# TC37X register map
File version: 1.0.0
CPU: CM4 r0p1, little endian, MPU, FPU, VTOR, 3 interrupt priority bits
Registers are 16-bit, read-write, reset 0x0 unless marked. A register's access mark holds for its fields unless they carry their own. Offsets are from the block's base; [hi:lo] are bit positions; {n}, {i} and the like mark numbered series; 'fields as' and 'values as' point back to an identical list.

## CCU60 — ce_ccusix
Base 0xF0002A00
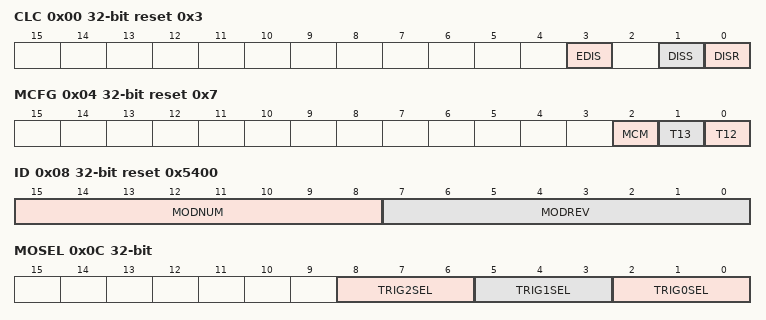
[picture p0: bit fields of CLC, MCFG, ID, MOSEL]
0x00 CLC 32-bit reset 0x3 — Clock Control Register
  [3] EDIS — Sleep Mode Enable Control - EDIS
  [1] DISS ro — Module Disable Status Bit - DISS
  [0] DISR — Module Disable Request Bit - DISR
0x04 MCFG 32-bit ro reset 0x7 — Module Configuration Register
  [2] MCM — Multi-Channel Mode Available - MCM
  [1] T13 — T13 Available - T13
  [0] T12 — T12 Available - T12
0x08 ID 32-bit ro reset 0x5400 (reset mask 0xFFFFFF00) — Module Identification Register
  [15:8] MODNUM — Module Number Value - MODNUM
  [7:0] MODREV — Module Revision Number - MODREV
0x0C MOSEL 32-bit — CCU60 Module Output Select Register
  [8:6] TRIG2SEL — Output Trigger Select for CCU6061 TRIG2
  [5:3] TRIG1SEL — Output Trigger Select for CCU6061 TRIG1
  [2:0] TRIG0SEL — Output Trigger Select for CCU6061 TRIG0
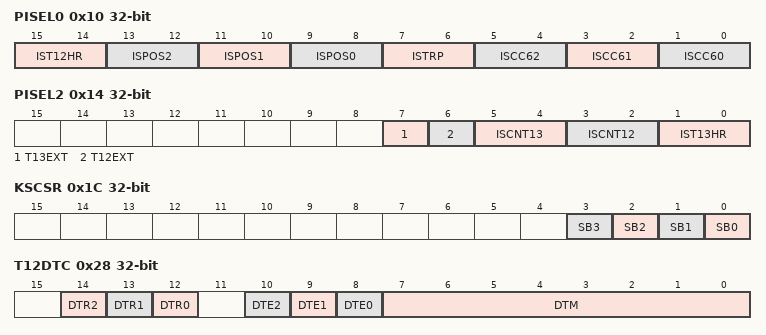
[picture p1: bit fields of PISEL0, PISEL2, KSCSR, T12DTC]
0x10 PISEL0 32-bit — Port Input Select Register 0
  [15:14] IST12HR — Input Select for T12HR - IST12HR
  [13:12] ISPOS2 — Input Select for CCPOS0 ISPOSx (x=0,1,2)
  [11:10] ISPOS1 — Input Select for CCPOS0 ISPOSx (x=0,1,2)
  [9:8] ISPOS0 — Input Select for CCPOS0 ISPOSx (x=0,1,2)
  [7:6] ISTRP — Input Select for CTRAP - ISTRP
  [5:4] ISCC62 — Input Select for CC60 ISCC6x (x=0,1,2)
  [3:2] ISCC61 — Input Select for CC60 ISCC6x (x=0,1,2)
  [1:0] ISCC60 — Input Select for CC60 ISCC6x (x=0,1,2)
0x14 PISEL2 32-bit — Port Input Select Register 2
  [7] T13EXT — Extension for T13HR Inputs - T13EXT
  [6] T12EXT — Extension for T12HR Inputs - T12EXT
  [5:4] ISCNT13 — Input Select for T13 Counting Input - ISCNT13
  [3:2] ISCNT12 — Input Select for T12 Counting Input - ISCNT12
  [1:0] IST13HR — Input Select for T13HR - IST13HR
0x1C KSCSR 32-bit — Kernel State Control Sensitivity Register
  [n] SB{n} (n=0..3) — Sensitivity Block x SBx (x=0,1,2,3)
0x20 T12 32-bit — Timer T12 Counter Register
  [15:0] T12CV — Timer 12 Counter Value - T12CV
0x24 T12PR 32-bit — Timer 12 Period Register
  [15:0] T12PV — T12 Period Value - T12PV
0x28 T12DTC 32-bit — Dead-Time Control Register for Timer12
  [14] DTR2 ro — Dead Time Run Indication Bits DTRx (x=1,2,3)
  [13] DTR1 ro — Dead Time Run Indication Bits DTRx (x=1,2,3)
  [12] DTR0 ro — Dead Time Run Indication Bits DTRx (x=1,2,3)
  [10] DTE2 — Dead Time Enable Bits DTEx (x=0,1,2)
  [9] DTE1 — Dead Time Enable Bits DTEx (x=0,1,2)
  [8] DTE0 — Dead Time Enable Bits DTEx (x=0,1,2)
  [7:0] DTM — Dead-Time - DTM
0x30 CC60R 32-bit ro — Capture/Compare Register for Channel CC60
  [15:0] CCV — Capture/Compare Value - CCV
0x34 CC61R 32-bit ro — Capture/Compare Register for Channel CC61
  [15:0] CCV — Capture/Compare Value - CCV
0x38 CC62R 32-bit ro — Capture/Compare Register for Channel CC62
  [15:0] CCV — Capture/Compare Value - CCV
0x40 CC60SR 32-bit — Capture/Compare Shadow Reg. for Channel CC60
  [15:0] CCS — Shadow Register for Channel x Capture/Compare Value - CCS
0x44 CC61SR 32-bit — Capture/Compare Shadow Reg. for Channel CC61
  fields as CC60SR
0x48 CC62SR 32-bit — Capture/Compare Shadow Reg. for Channel CC62
  fields as CC60SR
0x50 T13 32-bit — Timer T13 Counter Register
  [15:0] T13CV — Timer 13 Counter Value - T13CV
0x54 T13PR 32-bit — Timer 13 Period Register
  [15:0] T13PV — T13 Period Value - T13PV
0x58 CC63R 32-bit ro — Compare Register for T13
  [15:0] CCV — Channel CC63 Compare Value - CCV
0x5C CC63SR 32-bit — Compare Shadow Register for T13
  [15:0] CCS — Shadow Register for Channel CC63 Compare Value - CCS
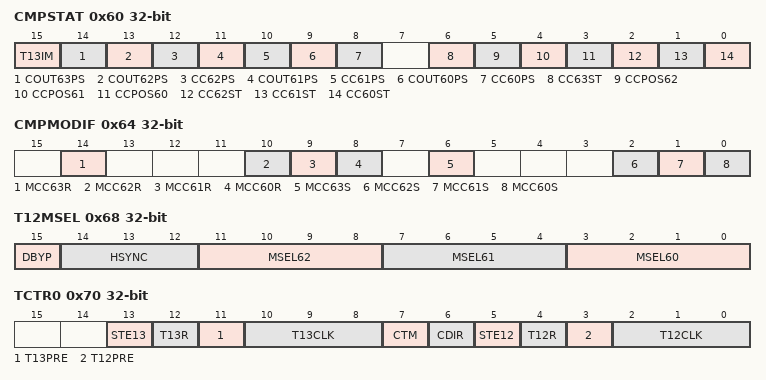
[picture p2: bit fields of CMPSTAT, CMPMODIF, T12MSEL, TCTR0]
0x60 CMPSTAT 32-bit — Compare State Register
  [15] T13IM — T13 Inverted Modulation - T13IM
  [14] COUT63PS — Passive State Select for Compare Output COUT63 - COUT63PS
  [13] COUT62PS — Passive State Select for Compare Outputs COUT62 (x = 0, 1, 2) - COUT62PS
  [12] CC62PS — Passive State Select for Compare Outputs CC62 (x = 0, 1, 2) - CC62PS
  [11] COUT61PS — Passive State Select for Compare Outputs COUT61 (x = 0, 1, 2) - COUT61PS
  [10] CC61PS — Passive State Select for Compare Outputs CC61 (x = 0, 1, 2) - CC61PS
  [9] COUT60PS — Passive State Select for Compare Outputs COUT60 (x = 0, 1, 2) - COUT60PS
  [8] CC60PS — Passive State Select for Compare Outputs CC60 (x = 0, 1, 2) - CC60PS
  [6] CC63ST ro — Capture/Compare State Bit for CC63 - CC63ST
  [5] CCPOS62 ro — Sampled Hall Pattern Bits - CCPOS62
  [4] CCPOS61 ro — Sampled Hall Pattern Bits - CCPOS61
  [3] CCPOS60 ro — Sampled Hall Pattern Bits - CCPOS60
  [2] CC62ST ro — Capture/Compare State Bits for CC62 (x = 0, 1, 2) - CC62ST
  [1] CC61ST ro — Capture/Compare State Bits for CC61 (x = 0, 1, 2) - CC61ST
  [0] CC60ST ro — Capture/Compare State Bits for CC60 (x = 0, 1, 2) - CC60ST
0x64 CMPMODIF 32-bit wo — Compare State Modification Register
  [14] MCC63R — Capture/Compare Status Modification Bits MCC63R - MCC63R
  [10] MCC62R — Capture/Compare Status Modification Bits MCC62R (x = 0, 1, 2) - MCC62R
  [9] MCC61R — Capture/Compare Status Modification Bits MCC61R (x = 0, 1, 2) - MCC61R
  [8] MCC60R — Capture/Compare Status Modification Bits MCC60R (x = 0, 1, 2) - MCC60R
  [6] MCC63S — Capture/Compare Status Modification Bit MCC63S - MCC63S
  [2] MCC62S — Capture/Compare Status Modification Bits MCC62S (x = 0, 1, 2) - MCC62S
  [1] MCC61S — Capture/Compare Status Modification Bits MCC61S (x = 0, 1, 2) - MCC61S
  [0] MCC60S — Capture/Compare Status Modification Bits MCC60S (x = 0, 1, 2) - MCC60S
0x68 T12MSEL 32-bit — T12 Mode Select Register
  [15] DBYP — Delay Bypass - DBYP
  [14:12] HSYNC — Hall Synchronization - HSYNC
  [11:8] MSEL62 — Capture/Compare Mode Selection MSEL6x (x=0,1,2)
  [7:4] MSEL61 — Capture/Compare Mode Selection MSEL6x (x=0,1,2)
  [3:0] MSEL60 — Capture/Compare Mode Selection MSEL6x (x=0,1,2)
0x70 TCTR0 32-bit — Timer Control Register 0
  [13] STE13 ro — Timer T13 Shadow Transfer Enable - STE13
  [12] T13R ro — Timer T13 Run Bit - T13R
  [11] T13PRE — Timer T13 Prescaler Bit - T13PRE
  [10:8] T13CLK — Timer T13 Input Clock Select - T13CLK
  [7] CTM — T12 Operating Mode - CTM
  [6] CDIR ro — Count Direction of Timer T12 - CDIR
  [5] STE12 ro — Timer T12 Shadow Transfer Enable - STE12
  [4] T12R ro — Timer T12 Run Bit - T12R
  [3] T12PRE — Timer T12 Prescaler Bit - T12PRE
  [2:0] T12CLK — Timer T12 Input Clock Select - T12CLK
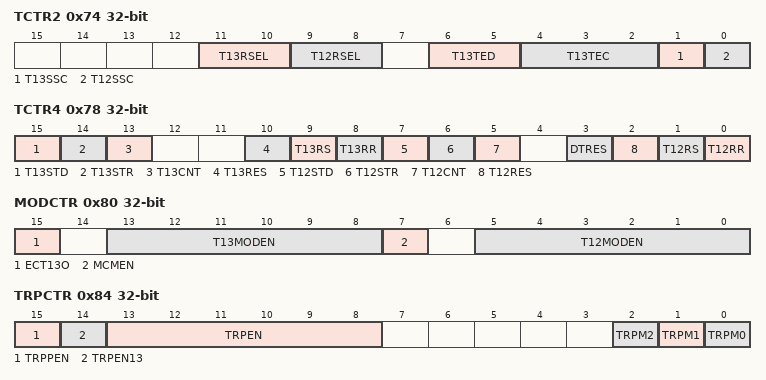
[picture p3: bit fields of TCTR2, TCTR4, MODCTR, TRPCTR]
0x74 TCTR2 32-bit — Timer Control Register 2
  [11:10] T13RSEL — Timer T13 External Run Selection - T13RSEL
  [9:8] T12RSEL — Timer T12 External Run Selection - T12RSEL
  [6:5] T13TED — Timer T13 Trigger Event Direction - T13TED
  [4:2] T13TEC — T13 Trigger Event Control - T13TEC
  [1] T13SSC — Timer T13 Single Shot Control - T13SSC
  [0] T12SSC — Timer T12 Single Shot Control - T12SSC
0x78 TCTR4 32-bit wo — Timer Control Register 4
  [15] T13STD — Timer T13 Shadow Transfer Disable - T13STD
  [14] T13STR — Timer T13 Shadow Transfer Request - T13STR
  [13] T13CNT — Timer T13 Count Event - T13CNT
  [10] T13RES — Timer T13 Reset - T13RES
  [9] T13RS — Timer T13 Run Set - T13RS
  [8] T13RR — Timer T13 Run Reset - T13RR
  [7] T12STD — Timer T12 Shadow Transfer Disable - T12STD
  [6] T12STR — Timer T12 Shadow Transfer Request - T12STR
  [5] T12CNT — Timer T12 Count Event - T12CNT
  [3] DTRES — Dead-Time Counter Reset - DTRES
  [2] T12RES — Timer T12 Reset - T12RES
  [1] T12RS — Timer T12 Run Set - T12RS
  [0] T12RR — Timer T12 Run Reset - T12RR
0x80 MODCTR 32-bit — Modulation Control Register
  [15] ECT13O — Enable Compare Timer T13 Output - ECT13O
  [13:8] T13MODEN — T13 Modulation Enable - T13MODEN
  [7] MCMEN — Multi-Channel Mode Enable - MCMEN
  [5:0] T12MODEN — T12 Modulation Enable - T12MODEN
0x84 TRPCTR 32-bit — Trap Control Register
  [15] TRPPEN — Trap Pin Enable - TRPPEN
  [14] TRPEN13 — Trap Enable Control for Timer T13 - TRPEN13
  [13:8] TRPEN — Trap Enable Control - TRPEN
  [2] TRPM2 — Trap Mode Control Bit 2 - TRPM2
  [1] TRPM1 — Trap Mode Control Bit 1 - TRPM1
  [0] TRPM0 — Trap Mode Control Bit 0 - TRPM0
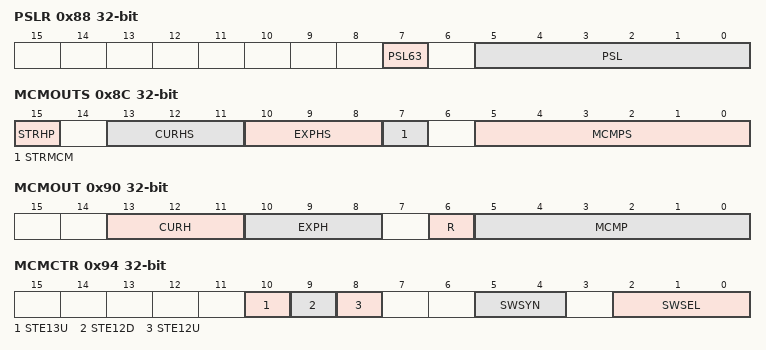
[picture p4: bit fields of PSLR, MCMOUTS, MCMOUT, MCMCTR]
0x88 PSLR 32-bit — Passive State Level Register
  [7] PSL63 — Passive State Level of Output COUT63 - PSL63
  [5:0] PSL — Compare Outputs Passive State Level - PSL
0x8C MCMOUTS 32-bit — Multi-Channel Mode Output Shadow Register
  [15] STRHP wo — Shadow Transfer Request for the Hall Pattern - STRHP
  [13:11] CURHS — Current Hall Pattern Shadow - CURHS
  [10:8] EXPHS — Expected Hall Pattern Shadow - EXPHS
  [7] STRMCM wo — Shadow Transfer Request for MCMPS - STRMCM
  [5:0] MCMPS — Multi-Channel PWM Pattern Shadow - MCMPS
0x90 MCMOUT 32-bit ro — Multi-Channel Mode Output Register
  [13:11] CURH — Current Hall Pattern - CURH
  [10:8] EXPH — Expected Hall Pattern - EXPH
  [6] R — Reminder Flag - R
  [5:0] MCMP — Multi-Channel PWM Pattern - MCMP
0x94 MCMCTR 32-bit — Multi-Channel Mode Control Register
  [10] STE13U — Shadow Transfer Enable for T13 Upcounting - STE13U
  [9] STE12D — Shadow Transfer Enable for T12 Downcounting - STE12D
  [8] STE12U — Shadow Transfer Enable for T12 Upcounting - STE12U
  [5:4] SWSYN — Switching Synchronization - SWSYN
  [2:0] SWSEL — Switching Selection - SWSEL
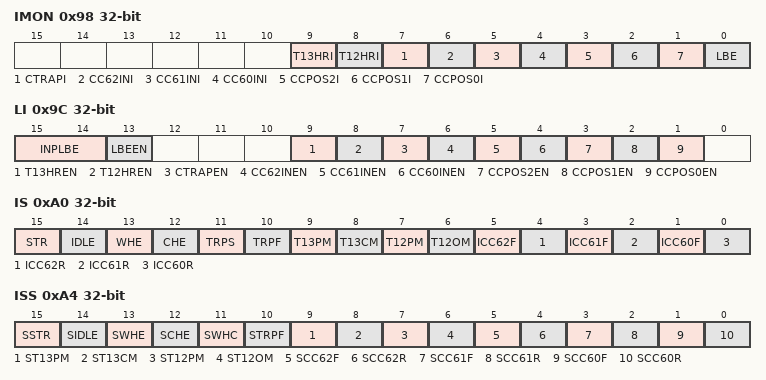
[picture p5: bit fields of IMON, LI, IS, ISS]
0x98 IMON 32-bit — Input Monitoring Register
  [9] T13HRI — Event indication for input signal T13HR - T13HRI
  [8] T12HRI — Event indication for input signal T12HR - T12HRI
  [7] CTRAPI — Event indication for input signal CTRAP - CTRAPI
  [6] CC62INI — Event indication for input signal CC62IN - CC62INI
  [5] CC61INI — Event indication for input signal CC61IN - CC61INI
  [4] CC60INI — Event indication for input signal CC60IN - CC60INI
  [3] CCPOS2I — Event indication for input signal CCPOS2 - CCPOS2I
  [2] CCPOS1I — Event indication for input signal CCPOS1 - CCPOS1I
  [1] CCPOS0I — Event indication for input signal CCPOS0 - CCPOS0I
  [0] LBE — Lost Bit Event - LBE
0x9C LI 32-bit — Lost Indicator Register
  [15:14] INPLBE — Interrupt Node Pointer for lost bit event - INPLBE
  [13] LBEEN — Interrupt Enable for Lost Bit Event - LBEEN
  [9] T13HREN — Lost Indicator Enable for input signal T13HR - T13HREN
  [8] T12HREN — Lost Indicator Enable for input signal T12HR - T12HREN
  [7] CTRAPEN — Lost Indicator Enable for input signal CTRAP - CTRAPEN
  [6] CC62INEN — Lost Indicator Enable for input signal CC62IN - CC62INEN
  [5] CC61INEN — Lost Indicator Enable for input signal CC61IN - CC61INEN
  [4] CC60INEN — Lost Indicator Enable for input signal CC60IN - CC60INEN
  [3] CCPOS2EN — Lost Indicator Enable for input signal CCPOS2 - CCPOS2EN
  [2] CCPOS1EN — Lost Indicator Enable for input signal CCPOS1 - CCPOS1EN
  [1] CCPOS0EN — Lost Indicator Enable for input signal CCPOS0 - CCPOS0EN
0xA0 IS 32-bit ro — Interrupt Status Register
  [15] STR — Multi-Channel Mode Shadow Transfer Request - STR
  [14] IDLE — IDLE State - IDLE
  [13] WHE — Wrong Hall Event - WHE
  [12] CHE — Correct Hall Event - CHE
  [11] TRPS — Trap State - TRPS
  [10] TRPF — Trap Flag - TRPF
  [9] T13PM — Timer T13 Period-Match Flag - T13PM
  [8] T13CM — Timer T13 Compare-Match Flag - T13CM
  [7] T12PM — Timer T12 Period-Match Flag - T12PM
  [6] T12OM — Timer T12 One-Match Flag - T12OM
  [5] ICC62F — Capture, Compare-Match Falling Edge Flag ICC6xF (x=0,1,2)
  [4] ICC62R — Capture, Compare-Match Rising Edge Flag ICC6xR (x=0,1,2)
  [3] ICC61F — Capture, Compare-Match Falling Edge Flag ICC6xF (x=0,1,2)
  [2] ICC61R — Capture, Compare-Match Rising Edge Flag ICC6xR (x=0,1,2)
  [1] ICC60F — Capture, Compare-Match Falling Edge Flag ICC6xF (x=0,1,2)
  [0] ICC60R — Capture, Compare-Match Rising Edge Flag ICC6xR (x=0,1,2)
0xA4 ISS 32-bit wo — Interrupt Status Set Register
  [15] SSTR — Set STR Flag - SSTR
  [14] SIDLE — Set IDLE Flag - SIDLE
  [13] SWHE — Set Wrong Hall Event Flag - SWHE
  [12] SCHE — Set Correct Hall Event Flag - SCHE
  [11] SWHC — Software Hall Compare - SWHC
  [10] STRPF — Set Trap Flag - STRPF
  [9] ST13PM — Set Timer T13 Period-Match Flag - ST13PM
  [8] ST13CM — Set Timer T13 Compare-Match Flag - ST13CM
  [7] ST12PM — Set Timer T12 Period-Match Flag - ST12PM
  [6] ST12OM — Set Timer T12 One-Match Flag - ST12OM
  [5] SCC62F — Set Capture, Compare-Match Falling Edge Flag - SCC6xF (x=0,1,2)
  [4] SCC62R — Set Capture, Compare-Match Rising Edge Flag - SCC6xR (x=0,1,2)
  [3] SCC61F — Set Capture, Compare-Match Falling Edge Flag - SCC6xF (x=0,1,2)
  [2] SCC61R — Set Capture, Compare-Match Rising Edge Flag - SCC6xR (x=0,1,2)
  [1] SCC60F — Set Capture, Compare-Match Falling Edge Flag - SCC6xF (x=0,1,2)
  [0] SCC60R — Set Capture, Compare-Match Rising Edge Flag - SCC6xR (x=0,1,2)
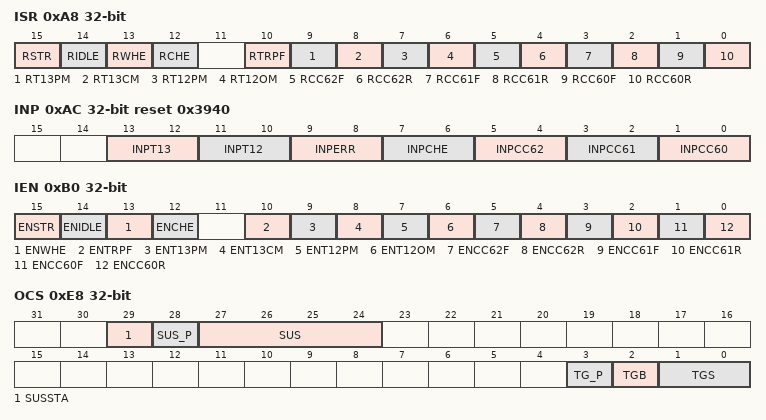
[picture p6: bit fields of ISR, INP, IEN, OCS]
0xA8 ISR 32-bit wo — Interrupt Status Reset Register
  [15] RSTR — Reset STR Flag - RSTR
  [14] RIDLE — Reset IDLE Flag - RIDLE
  [13] RWHE — Reset Wrong Hall Event Flag - RWHE
  [12] RCHE — Reset Correct Hall Event Flag - RCHE
  [10] RTRPF — Reset Trap Flag - RTRPF
  [9] RT13PM — Reset Timer T13 Period-Match Flag - RT13PM
  [8] RT13CM — Reset Timer T13 Compare-Match Flag - RT13CM
  [7] RT12PM — Reset Timer T12 Period-Match Flag - RT12PM
  [6] RT12OM — Reset Timer T12 One-Match Flag - RT12OM
  [5] RCC62F — Reset Capture, Compare-Match Falling Edge Flag - RCC6xF (x=0,1,2)
  [4] RCC62R — Reset Capture, Compare-Match Rising Edge Flag - RCC6xR (x=0,1,2)
  [3] RCC61F — Reset Capture, Compare-Match Falling Edge Flag - RCC6xF (x=0,1,2)
  [2] RCC61R — Reset Capture, Compare-Match Rising Edge Flag - RCC6xR (x=0,1,2)
  [1] RCC60F — Reset Capture, Compare-Match Falling Edge Flag - RCC6xF (x=0,1,2)
  [0] RCC60R — Reset Capture, Compare-Match Rising Edge Flag - RCC6xR (x=0,1,2)
0xAC INP 32-bit reset 0x3940 — Interrupt Node Pointer Register
  [13:12] INPT13 — Interrupt Node Pointer for Timer13 Interrupt - INPT13
  [11:10] INPT12 — Interrupt Node Pointer for Timer12 Interrupts - INPT12
  [9:8] INPERR — Interrupt Node Pointer for Error Interrupts - INPERR
  [7:6] INPCHE — Interrupt Node Pointer for the CHE Interrupt - INPCHE
  [5:4] INPCC62 — Interrupt Node Pointer for Channel CC6x Interrupts INPCC6x (x=0,1,2)
  [3:2] INPCC61 — Interrupt Node Pointer for Channel CC6x Interrupts INPCC6x (x=0,1,2)
  [1:0] INPCC60 — Interrupt Node Pointer for Channel CC6x Interrupts INPCC6x (x=0,1,2)
0xB0 IEN 32-bit — Interrupt Enable Register
  [15] ENSTR — Enable Multi-Channel Mode Shadow Transfer Interrupt - ENSTR
  [14] ENIDLE — Enable Idle - ENIDLE
  [13] ENWHE — Enable Interrupt for Wrong Hall Event - ENWHE
  [12] ENCHE — Enable Interrupt for Correct Hall Event - ENCHE
  [10] ENTRPF — Enable Interrupt for Trap Flag - ENTRPF
  [9] ENT13PM — Enable Interrupt for T13 Period-Match - ENT13PM
  [8] ENT13CM — Enable Interrupt for T13 Compare-Match - ENT13CM
  [7] ENT12PM — Enable Interrupt for T12 Period-Match - ENT12PM
  [6] ENT12OM — Enable Interrupt for T12 One-Match - ENT12OM
  [5] ENCC62F — Capture, Compare-Match Falling Edge Interrupt Enable for Channel CC6x ENCC6xF (x=0,1,2)
  [4] ENCC62R — Capture, Compare-Match Rising Edge Interrupt Enable for Channel CC6x ENCC6xF (x=0,1,2)
  [3] ENCC61F — Capture, Compare-Match Falling Edge Interrupt Enable for Channel CC6x ENCC6xF (x=0,1,2)
  [2] ENCC61R — Capture, Compare-Match Rising Edge Interrupt Enable for Channel CC6x ENCC6xF (x=0,1,2)
  [1] ENCC60F — Capture, Compare-Match Falling Edge Interrupt Enable for Channel CC6x ENCC6xF (x=0,1,2)
  [0] ENCC60R — Capture, Compare-Match Rising Edge Interrupt Enable for Channel CC6x ENCC6xF (x=0,1,2)
0xE8 OCS 32-bit — OCDS Control and Status Register
  [29] SUSSTA ro — Suspend State - SUSSTA
  [28] SUS_P wo — SUS Write Protection - SUS_P
  [27:24] SUS — OCDS Suspend Control - SUS
  [3] TG_P wo — TGS, TGB Write Protection - TG_P
  [2] TGB — OTGB0/1 Bus Select - TGB
  [1:0] TGS — Trigger Set for OTGB0/1 - TGS
0xEC KRSTCLR 32-bit wo — Kernel Reset Status Clear Register
  [0] CLR — Kernel Reset Status Clear - CLR
0xF0 KRST1 32-bit — Kernel Reset Register 1
  [0] RST — Kernel Reset - RST
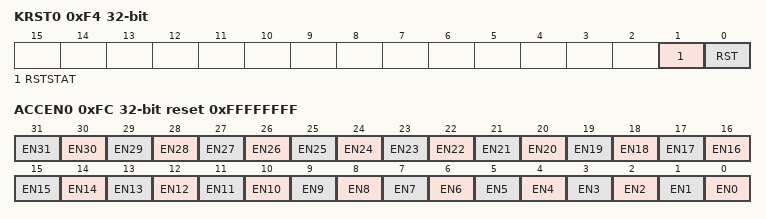
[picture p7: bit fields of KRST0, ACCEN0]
0xF4 KRST0 32-bit — Kernel Reset Register 0
  [1] RSTSTAT ro — Kernel Reset Status - RSTSTAT
  [0] RST — Kernel Reset - RST
0xFC ACCEN0 32-bit reset 0xFFFFFFFF — Access Enable Register 0
  [n] EN{n} (n=0..31) — Access Enable for Master TAG ID {n} - EN{n}

## CCU61 — ce_ccusix
Base 0xF0002B00
Registers as CCU60, without MOSEL.
